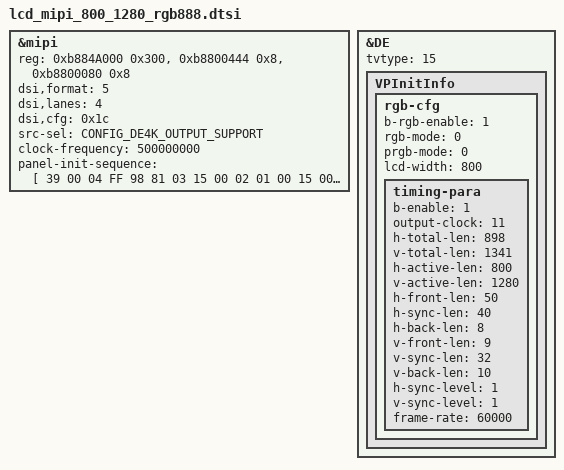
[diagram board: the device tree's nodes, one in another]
&mipi {
	reg = <0xb884A000 0x300>, <0xb8800444 0x8>,<0xb8800080 0x8>;

		/*
		 * MIPI_COLOR_RGB565_0	=	0
		 * MIPI_COLOR_RGB565_1	=	1
		 * MIPI_COLOR_RGB565_2	=	2
		 * MIPI_COLOR_RGB666_0	=	3
		 * MIPI_COLOR_RGB666_1	=	4
		 * MIPI_COLOR_RGB888	=	5
		*/
		dsi,format =<5>;

		dsi,lanes = <4>;

		/*
		 * bit 6:5 MIPI_Virtual_Channel_Generic_ID
		 * bit 4 :MIPI_CRC
		 * bit 3 :MIPI_ECC
		 * bit 2 :MIPI_Bus_Turn_request.
		 * bit 1 :MIPI_EOTp
		 * bit 0 :MIPI_EOTp
		 */
		dsi,cfg = <0x1c>;

		/*
		 * 0: E_SRC_SEL_FXDE = 0
		 * 1: E_SRC_SEL_4KDE
		 * 2: E_SRC_SEL_HDMI_RX
		 */
		src-sel = <CONFIG_DE4K_OUTPUT_SUPPORT>;
		clock-frequency = <500000000>;/*<1137124800>  1680307200 500000000;*/
		status = "okay";
};
&DE {
	tvtype = <15>;
	VPInitInfo {
		rgb-cfg{
			b-rgb-enable = <1>;
			/*
			 * 0: MODE_PRGB
			 * 1: MODE_SRGB
			 */
			rgb-mode = <0>;
			/*
			 * 0: MODE_PRGB_888_10bit 
			 * 1: MODE_PRGB_666
			 */
			prgb-mode = <0>; 
			lcd-width = <800>;

			timing-para {
				/* bool type, 0 or 1*/
				b-enable = <1>;
				/*
				 * VPO_RGB_CLOCK_27M = 1,
				 * VPO_RGB_CLOCK_33M = 2,
				 * VPO_RGB_CLOCK_49M = 3,
				 * VPO_RGB_CLOCK_66M = 4,
				 * VPO_RGB_CLOCK_74M = 5,
				 * VPO_RGB_CLOCK_85M = 6,
				 * VPO_RGB_CLOCK_108M = 7,
				 * VPO_RGB_CLOCK_6_6M = 8,
				 * VPO_RGB_CLOCK_9M = 9,
				 * VPO_RGB_CLOCK_39_6M = 10,
				 * VPO_RGB_CLOCK_74_25M = 11,	// H1600
				 * VPO_RGB_CLOCK_148_5M = 12,	// H1600
				 */
				output-clock = <11>;
				h-total-len = <898>;
				v-total-len = <1341>;

				h-active-len = <800>;
				v-active-len = <1280>;

				h-front-len = <50>;
				h-sync-len = <40>;
				h-back-len = <8>;//down

				v-front-len = <9>;
				v-sync-len = <32>;
				v-back-len = <10>;

				/* bool type, 0 or 1*/
				h-sync-level = <1>;
				/* bool type, 0 or 1*/
				v-sync-level = <1>;

				frame-rate = <60000>;
			};
		};
	};
};
&mipi{
panel-init-sequence = [
   39 00 04 FF 98 81 03
   15 00 02 01 00
   15 00 02 02 00
   15 00 02 03 53
   15 00 02 04 D3
   15 00 02 05 00
   15 00 02 06 0D
   15 00 02 07 08
   15 00 02 08 00
   15 00 02 09 00
   15 00 02 0a 00
   15 00 02 0b 00
   15 00 02 0c 00
   15 00 02 0d 00
   15 00 02 0e 00
   15 00 02 0f 28
   15 00 02 10 28
   15 00 02 11 00
   15 00 02 12 00
   15 00 02 13 00
   15 00 02 14 00
   15 00 02 15 00
   15 00 02 16 00
   15 00 02 17 00
   15 00 02 18 00
   15 00 02 19 00
   15 00 02 1a 00
   15 00 02 1b 00
   15 00 02 1c 00
   15 00 02 1d 00
   15 00 02 1e 40
   15 00 02 1f 80
   15 00 02 20 06
   15 00 02 21 01
   15 00 02 22 00
   15 00 02 23 00
   15 00 02 24 00
   15 00 02 25 00
   15 00 02 26 00
   15 00 02 27 00
   15 00 02 28 33
   15 00 02 29 33
   15 00 02 2a 00
   15 00 02 2b 00
   15 00 02 2c 00
   15 00 02 2d 00
   15 00 02 2e 00
   15 00 02 2f 00
   15 00 02 30 00
   15 00 02 31 00
   15 00 02 32 00
   15 00 02 33 00
   15 00 02 34 03
   15 00 02 35 00
   15 00 02 36 00
   15 00 02 37 00
   15 00 02 38 96
   15 00 02 39 00
   15 00 02 3a 00
   15 00 02 3b 00
   15 00 02 3c 00
   15 00 02 3d 00
   15 00 02 3e 00
   15 00 02 3f 00
   15 00 02 40 00
   15 00 02 41 00
   15 00 02 42 00
   15 00 02 43 00
   15 00 02 44 00
   15 00 02 50 00
   15 00 02 51 23
   15 00 02 52 45
   15 00 02 53 67
   15 00 02 54 89
   15 00 02 55 AB
   15 00 02 56 01
   15 00 02 57 23
   15 00 02 58 45
   15 00 02 59 67
   15 00 02 5a 89
   15 00 02 5b AB
   15 00 02 5c CD
   15 00 02 5d EF
   15 00 02 5e 00
   15 00 02 5f 08
   15 00 02 60 08
   15 00 02 61 06
   15 00 02 62 06
   15 00 02 63 01
   15 00 02 64 01
   15 00 02 65 00
   15 00 02 66 00
   15 00 02 67 02
   15 00 02 68 15
   15 00 02 69 15
   15 00 02 6a 14
   15 00 02 6b 14
   15 00 02 6c 0D
   15 00 02 6d 0D
   15 00 02 6e 0C
   15 00 02 6f 0C
   15 00 02 70 0F
   15 00 02 71 0F
   15 00 02 72 0E
   15 00 02 73 0E
   15 00 02 74 02
   15 00 02 75 08
   15 00 02 76 08
   15 00 02 77 06
   15 00 02 78 06
   15 00 02 79 01
   15 00 02 7a 01
   15 00 02 7b 00
   15 00 02 7c 00
   15 00 02 7d 02
   15 00 02 7e 15
   15 00 02 7f 15
   15 00 02 80 14
   15 00 02 81 14
   15 00 02 82 0D
   15 00 02 83 0D
   15 00 02 84 0C
   15 00 02 85 0C
   15 00 02 86 0F
   15 00 02 87 0F
   15 00 02 88 0E
   15 00 02 89 0E
   15 00 02 8A 02
   39 00 04 FF 98 81 04
   15 00 02 6E 2B
   15 00 02 6F 37
   15 00 02 3A A4
   15 00 02 8D 1A
   15 00 02 87 BA
   15 00 02 B2 D1
   15 00 02 88 0B
   15 00 02 38 01
   15 00 02 39 00
   15 00 02 B5 07
   15 00 02 31 75
   15 00 02 3B 98
   39 00 04 FF 98 81 01
   15 00 02 22 0A
   15 00 02 31 00
   15 00 02 53 48
   15 00 02 55 48
   15 00 02 50 99
   15 00 02 51 94
   15 00 02 60 10
   15 00 02 62 20
   15 00 02 A0 00
   15 00 02 A1 00
   15 00 02 A2 15
   15 00 02 A3 14
   15 00 02 A4 1B
   15 00 02 A5 2F
   15 00 02 A6 25
   15 00 02 A7 24
   15 00 02 A8 80
   15 00 02 A9 1F
   15 00 02 AA 2C
   15 00 02 AB 6C
   15 00 02 AC 16
   15 00 02 AD 14
   15 00 02 AE 4D
   15 00 02 AF 20
   15 00 02 B0 29
   15 00 02 B1 4F
   15 00 02 B2 5F
   15 00 02 B3 23
   15 00 02 C0 00
   15 00 02 C1 2E
   15 00 02 C2 3B
   15 00 02 C3 15
   15 00 02 C4 16
   15 00 02 C5 28
   15 00 02 C6 1A
   15 00 02 C7 1C
   15 00 02 C8 A7
   15 00 02 C9 1B
   15 00 02 CA 28
   15 00 02 CB 92
   15 00 02 CC 1F
   15 00 02 CD 1C
   15 00 02 CE 4B
   15 00 02 CF 1F
   15 00 02 D0 28
   15 00 02 D1 4E
   15 00 02 D2 5C
   15 00 02 D3 23
   39 00 04 FF 98 81 00
   05 78 01 11
   05 78 01 29
	];
};
